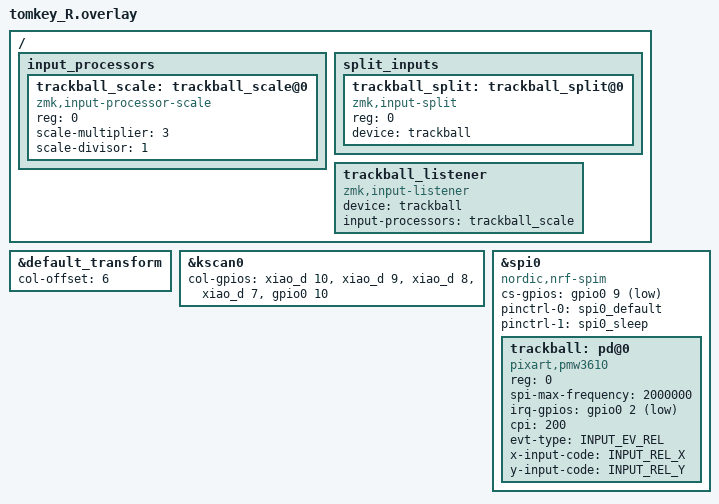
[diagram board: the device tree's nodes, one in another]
#include "tomkey.dtsi"
#include <input/processors.dtsi>
#include <dt-bindings/zmk/input_transform.h>

&default_transform {
    col-offset = <6>;
};

&kscan0 {
        col-gpios
            = <&xiao_d 10 GPIO_ACTIVE_HIGH>
            , <&xiao_d 9 GPIO_ACTIVE_HIGH>
            , <&xiao_d 8 GPIO_ACTIVE_HIGH>
            , <&xiao_d 7 GPIO_ACTIVE_HIGH>
            , <&gpio0 10 GPIO_ACTIVE_HIGH>
            ;
};

&spi0 {
    status = "okay";
    cs-gpios =  <&gpio0 9 GPIO_ACTIVE_LOW>;
    pinctrl-0 = <&spi0_default>;
    pinctrl-1 = <&spi0_sleep>;
    pinctrl-names = "default", "sleep";
    compatible = "nordic,nrf-spim";

    trackball: pd@0 {
        status = "disabled";
        compatible = "pixart,pmw3610";
        reg = <0>;
        spi-max-frequency = <2000000>;
        irq-gpios = <&gpio0 2 (GPIO_ACTIVE_LOW | GPIO_PULL_UP)>;
        cpi = <600>;
    };
};

/ {
    input_processors {
        #address-cells = <1>;
        #size-cells = <0>;

        trackball_scale: trackball_scale@0 {
            compatible = "zmk,input-processor-scale";
            reg = <0>;
            #input-processor-cells = <0>;
            scale-multiplier = <3>;  // 600 CPI相当 (200 * 3)
            scale-divisor = <1>;
        };
    };

    split_inputs {
        #address-cells = <1>;
        #size-cells = <0>;

        trackball_split: trackball_split@0 {
            compatible = "zmk,input-split";
            reg = <0>;
        };
    };

    trackball_listener: trackball_listener {
        compatible = "zmk,input-listener";
        status = "okay";
        device = <&trackball>;
        input-processors = <&trackball_scale>;
    };
};

&trackball {
    status = "okay";
	  irq-gpios = <&gpio0 2 (GPIO_ACTIVE_LOW | GPIO_PULL_UP)>;
    cpi = <200>;
    evt-type = <INPUT_EV_REL>;
    x-input-code = <INPUT_REL_X>;
    y-input-code = <INPUT_REL_Y>;
};

&trackball_split {
    device = <&trackball>;
};
